# RZN2L register map
Vendor: Renesas Electronics Corporation; Series: RZN; File version: 1.30.01
CPU: other r0p0, little endian, MPU, no FPU, VTOR, 4 interrupt priority bits, 624 interrupts
Registers are 32-bit, read-write, reset 0x0 unless marked. A register's access mark holds for its fields unless they carry their own. Offsets are from the block's base; [hi:lo] are bit positions; {n}, {i} and the like mark numbered series; 'fields as' and 'values as' point back to an identical list.

## ETHSW (part 2 of 3) — Ethernet Switch
Base 0x80120000
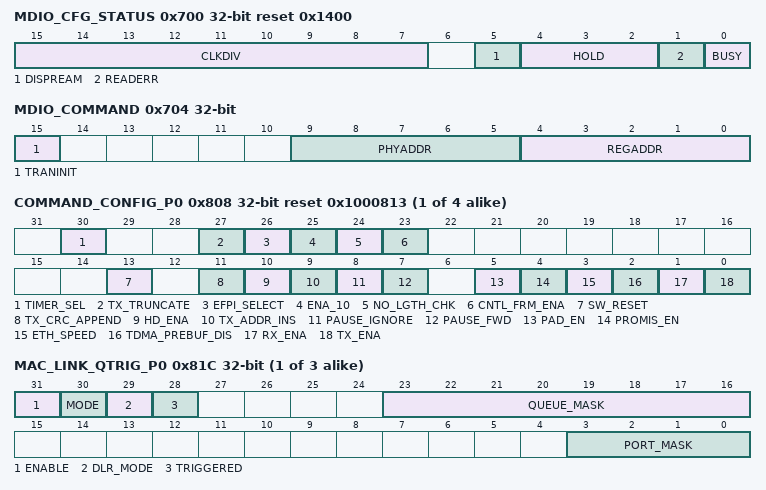
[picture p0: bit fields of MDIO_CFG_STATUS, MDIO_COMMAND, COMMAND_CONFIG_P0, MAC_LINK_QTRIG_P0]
0x700 MDIO_CFG_STATUS reset 0x1400 — MDIO Configuration and Status Register
  [15:7] CLKDIV — MDIO Clock Divisor
  [5] DISPREAM — Disable Preamble
    0=Enable Preamble; 1=Disable Preamble
  [4:2] HOLD — MDIO Hold Time Setting
    0=1 PCLKM clock cycle (default); 1=3 PCLKM clock cycles; 2=5 PCLKM clock cycles; 3=7 PCLKM clock cycles; 4=9 PCLKM clock cycles; 5=11 PCLKM clock cycles; 6=13 PCLKM clock cycles; 7=15 PCLKM clock cycles
  [1] READERR ro — MDIO Read Error
  [0] BUSY ro — MDIO Busy
0x704 MDIO_COMMAND — MDIO PHY Command Register
  [15] TRANINIT — If set to 1, a read transaction is initiated.
  [9:5] PHYADDR — PHY Address
  [4:0] REGADDR — Register Address
0x708 MDIO_DATA
  [15:0] MDIO_DATA
{0x800+0x400*i} REV_P{i} (i=0..3) ro reset 0x10002 (reset mask 0xFFFFFFFA) — Port {i} MAC Core Revision (n = 0 to 3)
  [31:0] REV — MAC Core Revision
{0x808+0x400*i} COMMAND_CONFIG_P{i} (i=0..3) reset 0x1000813 — Port {i} Command Configuration Register (n = 0 to 3)
  [30] TIMER_SEL — Selects the default timer to use for timestamping operations on transmit and on receive. The value is used when not overridden by the PTP auto-response function, pattern matchers or force forwarding information in a management tag.
    0=Use timer 0; 1=Use timer 1
  [27] TX_TRUNCATE
  [26] EFPI_SELECT
    0=EFP disable; 1=EFP enable
  [25] ENA_10 — This bit has no effect except PHYSPEED bit of STATUS_Pn register.
  [24] NO_LGTH_CHK — Payload Length Check Disable
  [23] CNTL_FRM_ENA — MAC Control Frame Enable
  [13] SW_RESET — Self Clearing Reset Command Bit
  [11] TX_CRC_APPEND — Enable CRC Append on Transmit
  [10] HD_ENA — Enable auto full/half-duplex operation (set to 1) or full-duplex only (set to 0).
  [9] TX_ADDR_INS ro — Non writable bit, fixed to 0 always.
  [8] PAUSE_IGNORE — Ignore Pause Frame Quanta
  [7] PAUSE_FWD ro — Terminate/Forward Pause Frames
  [5] PAD_EN ro — Enable/Disable Frame Padding Remove on Receive
  [4] PROMIS_EN ro — Enable/Disable MAC Promiscuous Operation
  [3] ETH_SPEED — Operation Mode Definition
    0=10/100 Megabit mode; 1=1 Gigabit mode
  [2] TDMA_PREBUF_DIS — When set to 1, the MAC does not request a new frame from the IMC until the current frame is completed. This can cause the IPG between frames to be more than the value in TX_IPG_LENGTH.
  [1] RX_ENA — Enable/Disable MAC Receive Path
  [0] TX_ENA — Enable/Disable MAC Transmit Path
{0x80C+0x400*i} MAC_ADDR_0_P{i} (i=0..2) — Port {i} MAC Address Register 0 (n = 0 to 2)
  [31:0] MAC_ADDR — The first 4 bytes of the MAC address of the port. First byte is bits [7:0]. The MAC address is used on locally generated frames such as pause frames, peer-delay response.
{0x810+0x400*i} MAC_ADDR_1_P{i} (i=0..2) — Port {i} MAC Address Register 1 (n = 0 to 2)
  [15:0] MAC_ADDR — The last 2 bytes of the MAC address of the port. Bits [7:0] is the 5th byte and bits [15:8] is the 6th byte.
{0x814+0x400*i} FRM_LENGTH_P{i} (i=0..3) reset 0x5FE — Port {i} Maximum Frame Length Register (n = 0 to 3)
  [13:0] FRM_LENGTH — Maximum Frame Length
{0x818+0x400*i} PAUSE_QUANT_P{i} (i=0..3) ro reset 0xFFFF — Port {i} MAC Pause Quanta (n = 0 to 3)
  [15:0] PAUSE_QUANT — Pause Quanta
{0x81C+0x400*i} MAC_LINK_QTRIG_P{i} (i=0..2) — Port {i} Trigger Event Configuration Register (n = 0 to 2)
  [31] ENABLE — Write to 1 to enable the Link Queue Trigger feature. When the link status (phy_link) transitions from 1 -> 0, a trigger event is generated to the memory controller for the ports and queues indicated in PORT_MASK and QUEUE_MASK.
  [30] MODE — When set to 0, only a single Link_Status frame is generated. This is to prevent sending multiple frames due to link flapping.
  [29] DLR_MODE — When set to 0, the DLR state machine is ignored. When set to 1, the Link Queue Trigger occurs only if the DLR state machine is in the NORMAL or FAULT state.
  [28] TRIGGERED — When MODE is set to 1, TRIGGERED indicates whether a frame was transmitted. When MODE is set to 0, TRIGGERED is always 0. This flag clears when the register is written.
  [23:16] QUEUE_MASK — 1-bit per queue indicating from which queues a frame is transmitted from the ports indicated by PORT_MASK. A single frame is transmitted per indicated port in PORT_MASK among the queues indicated by QUEUE_MASK.
  [3:0] PORT_MASK — Per-port Bit Mask
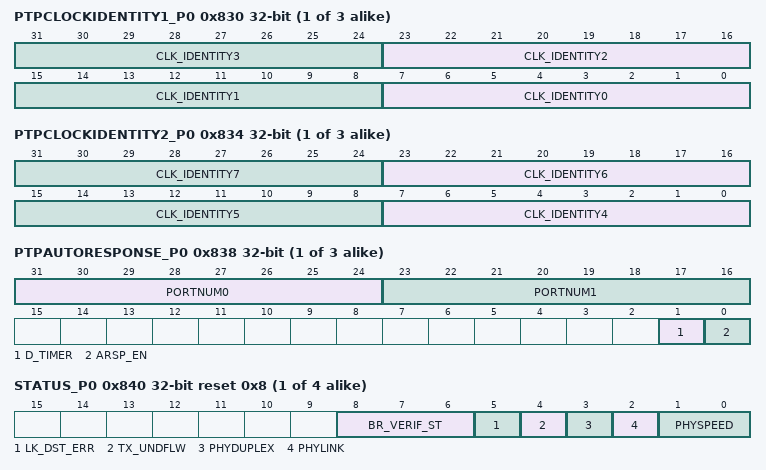
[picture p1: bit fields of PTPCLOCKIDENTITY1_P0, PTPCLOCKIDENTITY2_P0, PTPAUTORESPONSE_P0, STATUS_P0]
{0x830+0x400*i} PTPCLOCKIDENTITY1_P{i} (i=0..2) — Port {i} PTP Clock Identity 1 Register (n = 0 to 2)
  [8n+7:8n] CLK_IDENTITY{n} (n=0..3) — {n+20}, portIdentity.ClockIdentity[{n}]
{0x834+0x400*i} PTPCLOCKIDENTITY2_P{i} (i=0..2) — Port {i} PTP Clock Identity 2 Register (n = 0 to 2)
  [8n-25:8n-32] CLK_IDENTITY{n} (n=4..7) — {n+20}, portIdentity.ClockIdentity[{n}]
{0x838+0x400*i} PTPAUTORESPONSE_P{i} (i=0..2) — Port {i} PTP Auto Response Register (n = 0 to 2)
  [31:24] PORTNUM0 — 28, portIdentity.PortNumber[0] (msb)
  [23:16] PORTNUM1 — 29, portIdentity.PortNumber[1] (lsb)
  [1] D_TIMER — Default timer to use for auto-response generation
    0=Use timer 0; 1=Use timer 1
  [0] ARSP_EN — Auto Response Enable
{0x840+0x400*i} STATUS_P{i} (i=0..3) reset 0x8 (reset mask 0x1FC) — Port {i} Status Register
  [8:6] BR_VERIF_ST ro — Indicates the current status of the verification according to clause 30.14.1.2 of the 802.3br specification
    0=Unknown (during reset); 1=Initial (when preemption is disabled); 2=Verifying; 3=Succeeded; 4=Failed; 5=Disabled (if preempt verification is disabled)
  [5] LK_DST_ERR — Indicates that the L2 destination lookup process failed to complete in time before the next frame was received at the port. This should never occur under normal operation. The cause could be from IPG violations in the received frames.
  [4] TX_UNDFLW — Indicates that the transmit MAC underflow. This shall never occur during normal operation.
  [3] PHYDUPLEX ro — Duplex status from PHY interface
    0=half-duplex; 1=full-duplex
  [2] PHYLINK ro — Link status from PHY interface
    0=link down; 1=link up
  [1:0] PHYSPEED ro — Currently Active PHY Interface Speed
    0=10 Mbps; 1=100 Mbps; 2=1 Gbps
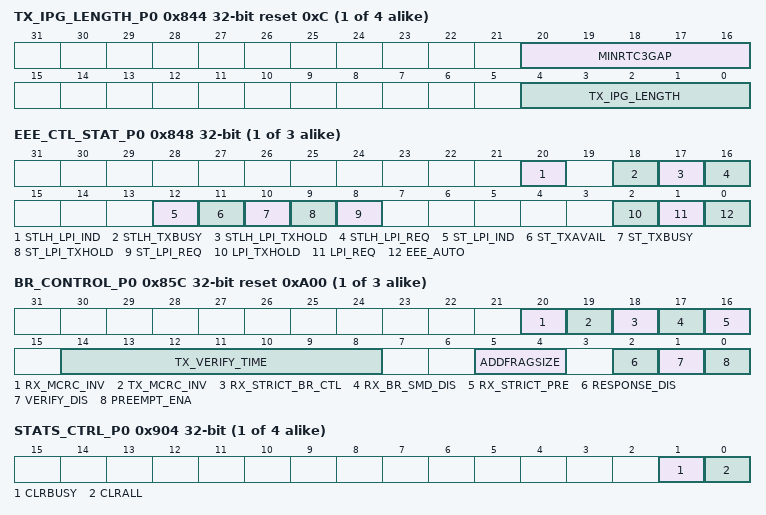
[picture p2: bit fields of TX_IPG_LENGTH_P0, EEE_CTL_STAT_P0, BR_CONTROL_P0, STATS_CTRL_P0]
{0x844+0x400*i} TX_IPG_LENGTH_P{i} (i=0..3) reset 0xC (reset mask 0x11001F) — Port {i} Transmit IPG Length Register (n = 0 to 3)
  [20:16] MINRTC3GAP
  [4:0] TX_IPG_LENGTH — Define transmit interpacket gap in octets. Allowed values are in the range of 8 to 31.
{0x848+0x400*i} EEE_CTL_STAT_P{i} (i=0..2) — Port {i} MAC EEE Functions Control and Status (n = 0 to 2)
  [20] STLH_LPI_IND ro — Status (latched high) of Received LPI (ST_LPI_IND)
  [18] STLH_TXBUSY ro — Status (latched high) if the MAC is/was Transmitting
  [17] STLH_LPI_TXHOLD ro — Status (latched high) of Internal LPI_TXHOLD to the MAC
  [16] STLH_LPI_REQ ro — Status (latched high) of Internal LPI_REQ to the MAC
  [12] ST_LPI_IND ro — Status (real time) of Received LPI
  [11] ST_TXAVAIL ro — Status (real time) if the MAC transmit FIFO has data available for transmission.
  [10] ST_TXBUSY ro — Status (real time) if the MAC is currently transmitting.
  [9] ST_LPI_TXHOLD ro — Status (real time) of Internal LPI_TXHOLD to the MAC
  [8] ST_LPI_REQ ro — Status (real time) of Internal LPI_REQ to the MAC
  [2] LPI_TXHOLD — MAC Transmission Hold
  [1] LPI_REQ — Request LPI Transmission when MAC Becomes Idle
  [0] EEE_AUTO — EEE Automatic Mode of Operation
{0x84C+0x400*i} EEE_IDLE_TIME_P{i} (i=0..2) — Port {i} EEE Idle Time Register (n = 0 to 2)
  [31:0] EEE_IDLE_TIME — Time (-1) the transmitter must be idle before transmission of LPI begins. A 32-bit value in steps of 32 switch operating clock cycles. A value of 0 disables the timer. The value must be set to 1 less count.
{0x850+0x400*i} EEE_TWSYS_TIME_P{i} (i=0..2) — Port {i} EEE Wake Up Time Register (n = 0 to 2)
  [31:0] EEE_WKUP_TIME — Time (-1) after PHY wakeup until the MAC is allowed to begin transmitting the first frame again. A 32-bit value in steps of switch operating clock cycles. A value of 0 disables the timer. The value must be set to 1 less count.
{0x854+0x400*i} IDLE_SLOPE_P{i} (i=0..3) — Port {i} MAC Traffic Shaper Bandwidth Control
  [10:0] IDLE_SLOPE — Traffic Shaper Bandwidth Control
{0x858+0x400*i} CT_DELAY_P{i} (i=0..2) — Port {i} Cut-Through Delay Indication Register
  [8:0] CT_DELAY — Delay Value in 400 ns / 40 ns / 8 ns increments (frequency of the MII PHY interface)
{0x85C+0x400*i} BR_CONTROL_P{i} (i=0..2) reset 0xA00 — Port {i} 802.3br Frame Configuration Register
  [20] RX_MCRC_INV — When set to 1, the 32-bit XOR mask used to calculate the mCRC for received frames is inverted. This bit must always be written to 0 and only used for debugging.
  [19] TX_MCRC_INV — When set to 1, the 32-bit XOR mask used to calculate the mCRC for transmitted frames is inverted. This bit must always be written to 0 and only used for debugging.
  [18] RX_STRICT_BR_CTL — When set to 1, strict checking of VERIFY and RESPONSE frames is enabled. When set to 1, the frame contents and frame length checks are also performed on these frames. The mCRC is always checked regardless of the value of this register. This bit must be set to 0 to be compliant with the functionality described in IEEE 802.3br.
  [17] RX_BR_SMD_DIS — When set to 1, the receiver does not decode the 802.3br SMDs and assumes all frames are express frames. This bit must be set to 0 for correct operation with 802.3br, and can be set to 1 when 802.3br is not enabled to avoid false detection of SMDs.
  [16] RX_STRICT_PRE — When set to 1, the preamble is checked so all bytes except the SFD are 0x55. When set to 0, only the last 2 bytes of the preamble are checked (SFD/SMD and FRAG_COUNT). It is recommended to set this bit to 1 to comply with the 802.3br specification. This bit must be set to 0 if only non-802.3br traffic is expected (for example, normal Ethernet traffic) and if custom preamble is used.
  [14:8] TX_VERIFY_TIME — Preemption verification timeout in milliseconds.
  [5:4] ADDFRAGSIZE — Minimum fragment size in increments of 64 bytes.
  [2] RESPONSE_DIS — When set to 1 prevents the MAC from responding to "verify" frames.
  [1] VERIFY_DIS — When set to 1, disables the verify process required for preemption operation.
  [0] PREEMPT_ENA — When set to 1, enables 802.3br Frame Preemption.
{0x868+0x400*i} AFRAMESTRANSMITTEDOK_P{i} (i=0..3) ro — Port {i} MAC Transmitted Valid Frame Count Register (n = 0 to 3)
  [31:0] TXVALIDCOUNT — PORT n, this field indicates the number of MAC Valid Transmitted, including pause.
{0x86C+0x400*i} AFRAMESRECEIVEDOK_P{i} (i=0..3) ro — Port {i} MAC Received Valid Frame Count Register (n = 0 to 3)
  [31:0] RXVALIDCOUNT — PORT n, this field indicates the number of MAC Valid Received, including pause.
{0x870+0x400*i} AFRAMECHECKSEQUENCEERRORS_P{i} (i=0..3) ro — Port {i} MAC FCS Error Frame Count Register (n = 0 to 3)
  [31:0] FCSERRCOUNT — PORT n, this field indicates the number of MAC Valid Length but CRC error.
{0x874+0x400*i} AALIGNMENTERRORS_P{i} (i=0..3) ro — Port {i} MAC Alignment Error Frame Count Register (n = 0 to 3)
  [31:0] ALGNERRCOUNT — PORT n, this field indicates the number of MAC Odd Number of Nibbles (MII) Received.
{0x878+0x400*i} AOCTETSTRANSMITTEDOK_P{i} (i=0..3) ro — Port {i} MAC Transmitted Valid Frame Octets Register (n = 0 to 3)
  [31:0] TXVALIDOCTETS — PORT n, this field indicates the octets (the payload only) of MAC Valid Transmitted.
{0x87C+0x400*i} AOCTETSRECEIVEDOK_P{i} (i=0..3) ro — Port {i} MAC Received Valid Frame Octets Register (n = 0 to 3)
  [31:0] RXVALIDOCTETS — PORT n, this field indicates the octets (the payload only) of MAC Valid Received.
{0x880+0x400*i} ATXPAUSEMACCTRLFRAMES_P{i} (i=0..3) ro — Port {i} MAC Transmitted Pause Frame Count Register (n = 0 to 3)
  [31:0] TXPAUSECOUNT — PORT n, this field indicates the number of MAC Valid Pause Transmitted.
{0x884+0x400*i} ARXPAUSEMACCTRLFRAMES_P{i} (i=0..3) ro — Port {i} MAC Received Pause Frame Count Register (n = 0 to 3)
  [31:0] RXPAUSECOUNT — PORT n, this field indicates the number of MAC Valid Pause Received.
{0x888+0x400*i} IFINERRORS_P{i} (i=0..3) ro — Port {i} MAC Input Error Count Register (n = 0 to 3)
  [31:0] INERRCOUNT — PORT n, this field indicates the number of MAC Any Error During Reception such as CRC, Length, PHY Error, RX FIFO Overflow.
{0x88C+0x400*i} IFOUTERRORS_P{i} (i=0..3) ro — Port {i} MAC Output Error Count Register (n = 0 to 3)
  [31:0] OUTERRCOUNT — PORT n, this field indicates the number of MAC Frame Transmitted with PHY error.
{0x890+0x400*i} IFINUCASTPKTS_P{i} (i=0..3) ro — Port {i} MAC Received Unicast Frame Count Register (n = 0 to 3)
  [31:0] RXUCASTCOUNT — PORT n, this field indicates the number of MAC Unicast Frame Valid Received.
{0x894+0x400*i} IFINMULTICASTPKTS_P{i} (i=0..3) ro — Port {i} MAC Received Multicast Frame Count Register (n = 0 to 3)
  [31:0] RXMCASTCOUNT — PORT n, this field indicates the number of MAC Multicast Frame Valid Received.
{0x898+0x400*i} IFINBROADCASTPKTS_P{i} (i=0..3) ro — Port {i} MAC Received Broadcast Frame Count Register (n = 0 to 3)
  [31:0] RXBCASTCOUNT — PORT n, this field indicates the number of MAC Broadcast Frame Valid Received.
{0x89C+0x400*i} IFOUTDISCARDS_P{i} (i=0..3) ro — Port {i} MAC Discarded Outbound Frame Count Register (n = 0 to 3)
  [31:0] DISCOBCOUNT — Not Applicable
{0x8A0+0x400*i} IFOUTUCASTPKTS_P{i} (i=0..3) ro — Port {i} MAC Transmitted Unicast Frame Count Register (n = 0 to 3)
  [31:0] TXUCASTCOUNT — PORT n, this field indicates the number of MAC Unicast Frame Valid Transmitted.
{0x8A4+0x400*i} IFOUTMULTICASTPKTS_P{i} (i=0..3) ro — Port {i} MAC Transmitted Multicast Frame Count Register (n = 0 to 3)
  [31:0] TXMCASTCOUNT — PORT n, this field indicates the number of MAC Multicast Frame Valid Transmitted.
{0x8A8+0x400*i} IFOUTBROADCASTPKTS_P{i} (i=0..3) ro — Port {i} MAC Transmitted Broadcast Frame Count Register (n = 0 to 3)
  [31:0] TXBCASTCOUNT — PORT n, this field indicates the number of MAC Broadcast Frame Valid Transmitted.
{0x8AC+0x400*i} ETHERSTATSDROPEVENTS_P{i} (i=0..3) ro — Port {i} MAC Dropped Frame Count Register (n = 0 to 3)
  [31:0] DROPCOUNT — PORT n, this field indicates the number of MAC RX FIFO Full at frame start.
{0x8B0+0x400*i} ETHERSTATSOCTETS_P{i} (i=0..3) ro — Port {i} MAC All Frame Octets Register (n = 0 to 3)
  [31:0] ALLOCTETS
{0x8B4+0x400*i} ETHERSTATSPKTS_P{i} (i=0..3) ro — Port {i} MAC All Frame Count Register (n = 0 to 3)
  [31:0] ALLCOUNT
{0x8B8+0x400*i} ETHERSTATSUNDERSIZEPKTS_P{i} (i=0..3) ro — Port {i} MAC Too Short Frame Count Register (n = 0 to 3)
  [31:0] TOOSHRTCOUNT — PORT n, this field indicates the number of MAC too Short, Good CRC.
{0x8BC+0x400*i} ETHERSTATSOVERSIZEPKTS_P{i} (i=0..3) ro — Port {i} MAC Too Long Frame Count Register (n = 0 to 3)
  [31:0] TOOLONGCOUNT — PORT n, this field indicates the number of MAC too Long, Good CRC.
{0x8C0+0x400*i} ETHERSTATSPKTS64OCTETS_P{i} (i=0..3) ro — Port {i} MAC 64 Octets Frame Count Register (n = 0 to 3)
  [31:0] OCTCNT64 — PORT n, this field indicates the number of MAC All Frames, Good and Bad (Packet Size: 64 bytes).
{0x8C4+0x400*i} ETHERSTATSPKTS65TO127OCTETS_P{i} (i=0..3) ro — Port {i} MAC 65 to 127 Octets Frame Count Register (n = 0 to 3)
  [31:0] OCTCNT65T127 — PORT n, this field indicates the number of MAC All Frames, Good and Bad (Packet Size: 65 to 127 bytes).
{0x8C8+0x400*i} ETHERSTATSPKTS128TO255OCTETS_P{i} (i=0..3) ro — Port {i} MAC 128 to 255 Octets Frame Count Register (n = 0 to 3)
  [31:0] OCTCNT128T255 — PORT n, this field indicates the number of MAC All Frames, Good and Bad (Packet Size: 128 to 255 bytes).
{0x8CC+0x400*i} ETHERSTATSPKTS256TO511OCTETS_P{i} (i=0..3) ro — Port {i} MAC 256 to 511 Octets Frame Count Register (n = 0 to 3)
  [31:0] OCTCNT256T511 — PORT n, this field indicates the number of MAC All Frames, Good and Bad (Packet Size: 256 to 511 bytes).
{0x8D0+0x400*i} ETHERSTATSPKTS512TO1023OCTETS_P{i} (i=0..3) ro — Port {i} MAC 512 to 1023 Octets Frame Count Register (n = 0 to 3)
  [31:0] OCTCNT512T1023 — PORT n, this field indicates the number of MAC All Frames, Good and Bad (Packet Size: 512 to 1023 bytes).
{0x8D4+0x400*i} ETHERSTATSPKTS1024TO1518OCTETS_P{i} (i=0..3) ro — Port {i} MAC 1024 to 1518 Octets Frame Count Register (n = 0 to 3)
  [31:0] OCTCNT1024T1518 — PORT n, this field indicates the number of MAC All Frames, Good and Bad (Packet Size: 1024 to 1518 bytes).
{0x8D8+0x400*i} ETHERSTATSPKTS1519TOXOCTETS_P{i} (i=0..3) ro — Port {i} MAC Over 1519 Octets Frame Count Register (n = 0 to 3)
  [31:0] OCTCNT1519TX — PORT n, this field indicates the number of MAC all Frames, Good and Bad (Packet Size: over 1519 bytes).
{0x8DC+0x400*i} ETHERSTATSJABBERS_P{i} (i=0..3) ro — Port {i} MAC Jabbers Frame Count Register (n = 0 to 3)
  [31:0] JABBERCOUNT — PORT n, this field indicates the number of MAC too Long, Bad CRC.
{0x8E0+0x400*i} ETHERSTATSFRAGMENTS_P{i} (i=0..3) ro — Port {i} MAC Fragment Frame Count Register (n = 0 to 3)
  [31:0] FRAGCOUNT — PORT n, this field indicates the number of MAC too Short, Bad CRC.
{0x8E8+0x400*i} VLANRECEIVEDOK_P{i} (i=0..3) ro — Port {i} MAC Received VLAN Tagged Frame Count Register (n = 0 to 3)
  [31:0] RXVLANTAGCNT — PORT n, this field indicates the number of Good Frames with VLAN Tag Received.
{0x8F4+0x400*i} VLANTRANSMITTEDOK_P{i} (i=0..3) ro — Port {i} MAC Transmitted VLAN Tagged Frame Count Register (n = 0 to 3)
  [31:0] TXVLANTAGCNT — PORT n, this field indicates the number of Good Frames with VLAN Tag Transmitted.
{0x8F8+0x400*i} FRAMESRETRANSMITTED_P{i} (i=0..3) ro — Port {i} MAC Retransmitted Frame Count Register (n = 0 to 3)
  [31:0] RETXCOUNT — PORT n, this field indicates the number of Transmitted Frames that experienced a collision and were retransmitted.
{0x900+0x400*i} STATS_HIWORD_P{i} (i=0..3) ro — Port {i} MAC Statistics Counter High Word Register (n = 0 to 3)
  [31:0] STATS_HIWORD — The latched upper 32-bit of the 64 bits MAC Statistics Counter Last Read
{0x904+0x400*i} STATS_CTRL_P{i} (i=0..3) — Port {i} MAC Statistics Control Register (n = 0 to 3)
  [1] CLRBUSY ro — Clear in Progress Indication
  [0] CLRALL — Self Clearing Counter Initialize Command
{0x908+0x400*i} STATS_CLEAR_VALUELO_P{i} (i=0..3) — Port {i} MAC Statistics Clear Value Lower Register (n = 0 to 3)
  [31:0] STATS_CLEAR_VALUELO — PORT n, lower 32-bit of 64 bits value loaded into all counters when clearing all counters with STATS_CTRL_Pn.CLRALL command for test purposes. These bits should be set to 0 normally.
{0x90C+0x400*i} STATS_CLEAR_VALUEHI_P{i} (i=0..3) — Port {i} MAC Statistics Clear Value Higher Register (n = 0 to 3)
  [31:0] STATS_CLEAR_VALUEHI — PORT n, upper 32-bit of 64 bits value loaded into all counters when clearing all counters with STATS_CTRL_Pn.CLRALL command for test purposes. These bits should be set to 0 normally.
{0x910+0x400*i} ADEFERRED_P{i} (i=0..3) ro — Port {i} MAC Deferred Count Register (n = 0 to 3)
  [31:0] DEFERCOUNT — PORT n, this field indicates the number of Frame Transmitted without collision but was deferred at begin.
{0x914+0x400*i} AMULTIPLECOLLISIONS_P{i} (i=0..3) ro — Port {i} MAC Multiple Collision Count Register (n = 0 to 3)
  [31:0] COUNTAFTMLTCOLL — PORT n, this field indicates the number of Good Frame Transmit after multiple collisions.
{0x918+0x400*i} ASINGLECOLLISIONS_P{i} (i=0..3) ro — Port {i} MAC Single Collision Count Register (n = 0 to 3)
  [31:0] COUNTAFTSNGLCOLL — PORT n, this field indicates the number of Good Frame Transmit after single collision.
{0x91C+0x400*i} ALATECOLLISIONS_P{i} (i=0..3) ro — Port {i} MAC Late Collision Count Register (n = 0 to 3)
  [31:0] LATECOLLCOUNT — PORT n, this field indicates the number of too Late Collision. Frame was aborted and not retransmitted.
{0x920+0x400*i} AEXCESSIVECOLLISIONS_P{i} (i=0..3) ro — Port {i} MAC Excessive Collision Count Register (n = 0 to 3)
  [31:0] EXCCOLLCOUNT — PORT n, this field indicates the number of Frames Discarded due to 16 consecutive collisions.
{0x924+0x400*i} ACARRIERSENSEERRORS_P{i} (i=0..3) ro — Port {i} MAC Carrier Sense Error Count Register (n = 0 to 3)
  [31:0] CSERRCOUNT — PORT n, increments during Transmission without Collisions the PHY Carrier Sense Signal (RX_CRS) dropped or never asserted.
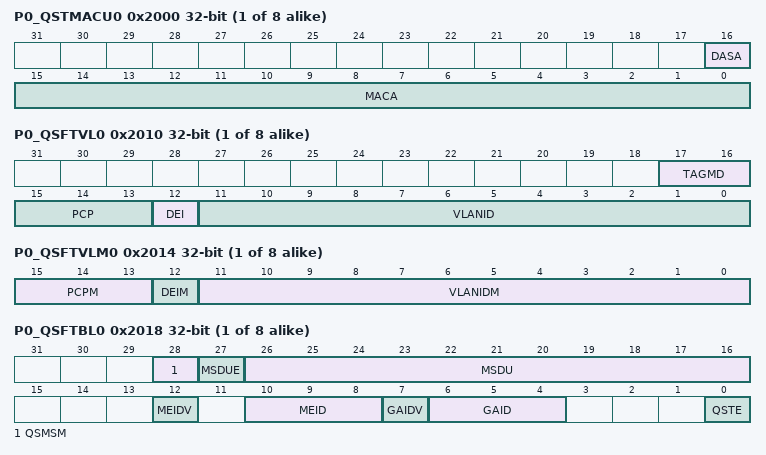
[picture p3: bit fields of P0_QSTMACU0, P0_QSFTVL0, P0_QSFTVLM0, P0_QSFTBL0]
{0x2000+0x28*i} P0_QSTMACU{i} (i=0..7) — Qci Stream Filter Table MAC Address Upper Part
  [16] DASA — MAC address (MACA) select
    0=MACA is a source address; 1=MACA is a destination address
  [15:0] MACA — Qci stream filter table MAC address[47:32]
{0x2004+0x28*i} P0_QSTMACD{i} (i=0..7) — Qci Stream Filter Table MAC Address Downer Part
  [31:0] MACA — Qci stream filter table MAC address[31:0]
{0x2008+0x28*i} P0_QSTMAMU{i} (i=0..7) — Qci Stream Filter Table MAC Address Mask Upper Part
  [15:0] MACAM — Qci stream filter table MAC address bit mask[47:32]
{0x200C+0x28*i} P0_QSTMAMD{i} (i=0..7) — Qci Stream Filter Table MAC Address Mask Downer Part
  [31:0] MACAM — Qci stream filter table MAC address bit mask[31:0]
{0x2010+0x28*i} P0_QSFTVL{i} (i=0..7) — Qci Stream Filter Table VLAN
  [17:16] TAGMD
    0=Un Tagged (the frame must be untagged to match to this filter); 1=C-Tagged (the frame must be C-Tagged to match to this filter); 3=Do not check VLAN Tag (VLAN Tag check is skipped. All frames either untagged or tagged with any VLAN/PCP/DEI may match this filter.)
  [15:13] PCP
  [12] DEI
  [11:0] VLANID
{0x2014+0x28*i} P0_QSFTVLM{i} (i=0..7) — Qci Stream Filter Table VLAN Mask
  [15:13] PCPM — Qci stream filter table VLAN PCP[2:0] bit mask
  [12] DEIM
    0=No bit mask; 1=Bit mask (the bit value of the DEI is ignored, any value matches)
  [11:0] VLANIDM — Qci stream filter table VLAN ID[11:0] bit mask
{0x2018+0x28*i} P0_QSFTBL{i} (i=0..7) — Qci Stream Filter Table SDU/Gate/Meter ID
  [28] QSMSM — Qci stream MSDU mode
    0=No effect; 1=When a frame is discard by MSDU over, all frames are dropped until software clears Pn_QSEIS.QSMOIS[s]
  [27] MSDUE
    0=Check disable; 1=Check enable
  [26:16] MSDU — Qci stream filter table max SDU size
  [12] MEIDV
    0=Meter Check disable; 1=Meter Check enable
  [10:8] MEID
  [7] GAIDV
    0=Gating Check disable; 1=Gating Check enable
  [6:4] GAID
  [0] QSTE
    0=Stream filter Table disable (All frame unmatch); 1=Stream filter Table enable
{0x201C+0x28*i} P0_QSMFC{i} (i=0..7) ro — Qci Stream Match Packet Count
  [15:0] QSMFC — Qci stream match packet count
{0x2020+0x28*i} P0_QMSPPC{i} (i=0..7) ro — Qci MSDU Passed Packet Count
  [15:0] QMSPPC — Qci msdu passed packet count
{0x2024+0x28*i} P0_QMSRPC{i} (i=0..7) ro — Qci MSDU Reject Packet Count
  [15:0] QMSRPC — Qci MSDU rejected packet count
{0x21E8+0x400*i} P{i}_QSEIS (i=0..2) — Qci Stream Filter Error Interrupt Status (SDU Oversize)
  [7:0] QSMOIS — MSDU oversize frames Interrupt status[s]
{0x21EC+0x400*i} P{i}_QSEIE (i=0..2) — Qci Stream Filter Error Interrupt Enable
  [7:0] QSMOIE — MSDU oversize frames Interrupt Enable[s]
{0x21F0+0x400*i} P{i}_QSEID (i=0..2) wo — Qci Stream Filter Error Interrupt Disable
  [7:0] QSMOID — MSDU oversize frames Interrupt Disable[s]
{0x2200+0x400*i} P{i}_QGMOD (i=0..2) — Qci Gate Mode Register
  [7:0] QGMOD — Flow gate mode[g]
{0x2204+0x400*i} P{i}_QGPPC (i=0..2) ro — Qci Gate (All) Passed Packet Count Port {i}
  [15:0] QGPPC — Qci gate passed packet count
{0x2208+8i} P0_QGDPC{i} (i=0..7) ro — Qci Gate {i} Dropped Packet Count Port n
  [15:0] QGDPC — Qci gate dropped packet count
{0x2244+0x400*i} P{i}_QGEIS (i=0..2) — Qci Gate Error Interrupt Status
  [7:0] QGMOIS — Gating error Interrupt status[g]
{0x2248+0x400*i} P{i}_QGEIE (i=0..2) — Qci Gate Error Interrupt Enable
  [7:0] QGMOIE — Gating error Interrupt Enable[g]
{0x224C+0x400*i} P{i}_QGEID (i=0..2) wo — Qci Gate Error Interrupt Disable
  [7:0] QGMOID — Gating error Interrupt Disable[g]
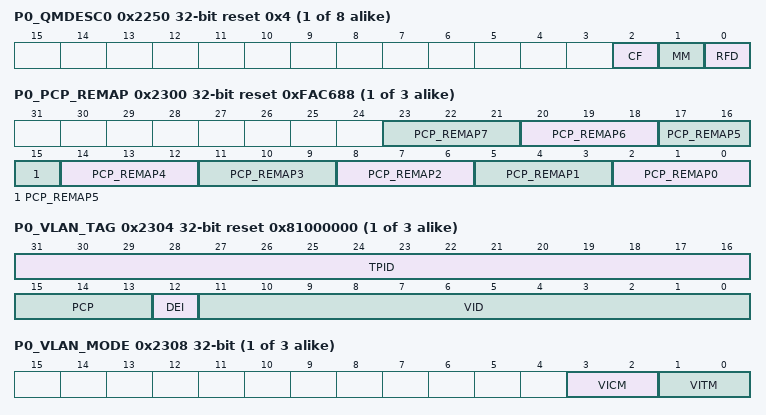
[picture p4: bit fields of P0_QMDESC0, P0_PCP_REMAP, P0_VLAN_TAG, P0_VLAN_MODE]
{0x2250+0x14*i} P0_QMDESC{i} (i=0..7) reset 0x4 — Qci Port n Flow Meter {i} Descriptor Register
  [2] CF — Coupling flag
  [1] MM — Flow meter mode
    0=No effect; 1=When discard frame by Flow Meter, all frames are dropped until software clears Pn_QMEIS.QRFIS[m]
  [0] RFD — Red frame drop
    0=A red frame is not dropped; 1=A red frame is dropped
{0x2254+0x14*i} P0_QMCBSC{i} (i=0..7) — Qci Meter CBS Configuration Port n, Meter {i}
  [17:0] CBS — CBS (Committed Burst Size)
{0x2258+0x14*i} P0_QMCIRC{i} (i=0..7) — Qci Meter CIR Configuration n {i}
  [16:0] CIR — CIR (Committed Information Rate)
{0x225C+0x14*i} P0_QMGPC{i} (i=0..7) ro — Qci Meter Green Packet Count
  [15:0] QMGPC — Qci meter green packet count
{0x2260+0x14*i} P0_QMRPC{i} (i=0..7) ro — Qci Meter Red Packet Count
  [15:0] QMRPC — Qci meter red packet count
{0x22F0+0x400*i} P{i}_QMEC (i=0..2) — Qci Meter Enable Configuration
  [7:0] ME — Enable meter[m]
{0x22F4+0x400*i} P{i}_QMEIS (i=0..2) — Qci Meter Error Interrupt Status
  [7:0] QRFIS — Red frames Interrupt status[m]
{0x22F8+0x400*i} P{i}_QMEIE (i=0..2) — Qci Meter Error Interrupt Enable
  [7:0] QRFIE — Red frames Interrupt Enable[m]
{0x22FC+0x400*i} P{i}_QMEID (i=0..2) wo — Qci Meter Error Interrupt Disable
  [7:0] QRFID — Red frames Interrupt Disable[m]
{0x2300+0x400*i} P{i}_PCP_REMAP (i=0..2) reset 0xFAC688 — Port {i} VLAN Priority Code Point (PCP) Remap
  [3n+2:3n] PCP_REMAP{n} (n=0..7)
{0x2304+0x400*i} P{i}_VLAN_TAG (i=0..2) reset 0x81000000 — Port {i} VLAN TAG Information for Priority Regeneration
  [31:16] TPID, [15:13] PCP, [12] DEI, [11:0] VID
{0x2308+0x400*i} P{i}_VLAN_MODE (i=0..2) — Port {i} VLAN Mode
  [3:2] VICM — VLAN input verification mode
    {v}=Mode {v} (v=0..3)
  [1:0] VITM — VLAN input tagging mode
    0=Disabled, VLAN tag is neither added nor overwritten; 1=Single Tagging with Passthrough/ VLAN ID (VID) Overwrite; 2=Single Tagging with Replace; 3=Tag always
{0x230C+0x400*i} P{i}_VIC_DROP_CNT (i=0..2) ro — Port {i} VLAN Ingress Check Drop Frame Counter
  [15:0] VIC_DROP_CNT — Port n VLAN ingress check drop frame count
{0x2328+0x400*i} P{i}_LOOKUP_HIT_CNT (i=0..2) ro — Port {i} DST Address Lookup Hit Counter
  [23:0] LOOKUP_HIT_CNT — Port n Lookup hit count
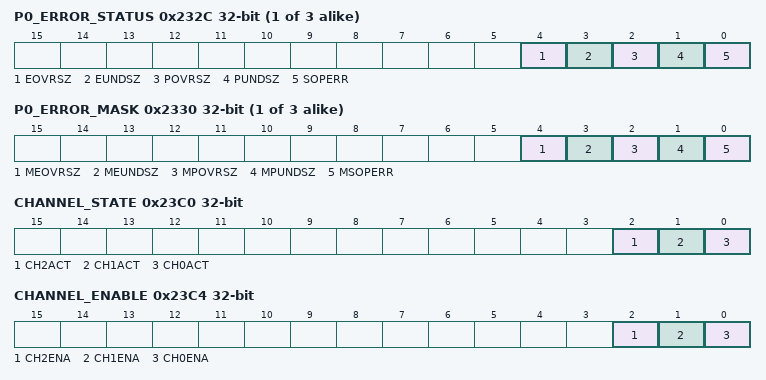
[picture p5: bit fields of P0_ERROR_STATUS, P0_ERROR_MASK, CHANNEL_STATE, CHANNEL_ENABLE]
{0x232C+0x400*i} P{i}_ERROR_STATUS (i=0..2) — Port {i} Frame Parser Runtime Error Status
  [4] EOVRSZ — Express frame over size error detected in frame parser
  [3] EUNDSZ — Express frame under size error detected in frame parser
  [2] POVRSZ — Preemptable frame over size error detected in frame parser
  [1] PUNDSZ — Preemptable frame under size error detected in frame parser
  [0] SOPERR — SOP error detected in frame parser
{0x2330+0x400*i} P{i}_ERROR_MASK (i=0..2) — Port {i} Frame Parser Runtime Error Mask
  [4] MEOVRSZ — Error mask of EOVRSZ (Express frame over size error)
  [3] MEUNDSZ — Error mask of EUNDSZ (Express frame under size error)
  [2] MPOVRSZ — Error mask of POVRSZ (Preemptable frame over size error)
  [1] MPUNDSZ — Error mask of PUNDSZ (Preemptable frame under size error)
  [0] MSOPERR — Error mask of SOPERR (SOP error)
0x23C0 CHANNEL_STATE ro — Enable/Disable State of Ingress Channels
  [2] CH2ACT
    0=Channel port 2 is in reset. No frames are forwarded.; 1=Channel port 2 is enabled. Frames are forwarded and manipulated as configured.
  [1] CH1ACT
    0=Channel port 1 is in reset. No frames are forwarded.; 1=Channel port 1 is enabled. Frames are forwarded and manipulated as configured.
  [0] CH0ACT
    0=Channel port 0 is in reset. No frames are forwarded.; 1=Channel port 0 is enabled. Frames are forwarded and manipulated as configured.
0x23C4 CHANNEL_ENABLE wo reset not defined — Enable Operation of Channel
  [2] CH2ENA
    0=Ignored; 1=Enable Channel port 2
  [1] CH1ENA
    0=Ignored; 1=Enable Channel port 1
  [0] CH0ENA
    0=Ignored; 1=Enable Channel port 0
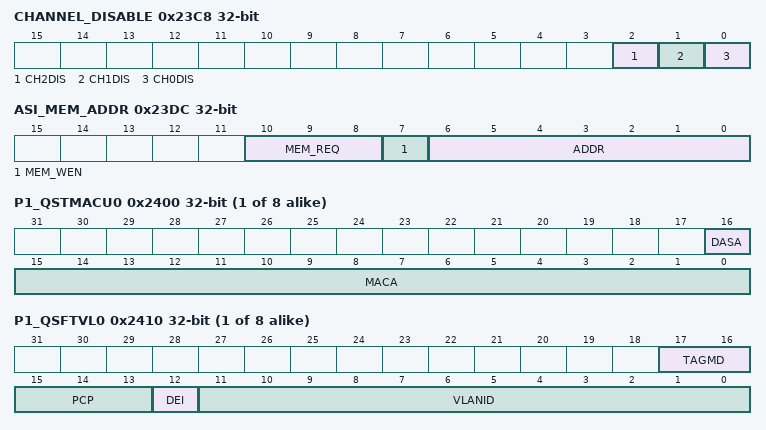
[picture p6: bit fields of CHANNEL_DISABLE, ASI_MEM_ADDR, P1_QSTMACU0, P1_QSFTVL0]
0x23C8 CHANNEL_DISABLE wo reset not defined — Disable and Reset Operation of Channel
  [2] CH2DIS
    0=Ignored; 1=Disable and reset Channel port 2
  [1] CH1DIS
    0=Ignored; 1=Disable and reset Channel port 1
  [0] CH0DIS
    0=Ignored; 1=Disable and reset Channel port 0
{0x23CC+4i} ASI_MEM_WDATA{i} (i=0..3) — Memory Write Data Word {i}
  [31:0] WDATA — Destination MAC address regeneration write data
0x23DC ASI_MEM_ADDR — Memory Address and R/W Control
  [10:8] MEM_REQ — Memory access request
  [7] MEM_WEN
    0=Read; 1=Write
  [6:0] ADDR — Memory access address
{0x23E0+4i} ASI_MEM_RDATA{i} (i=0..3) ro — Memory Read Data Word {i}
  [31:0] RDATA — Destination MAC address regeneration read data
{0x2400+0x28*i} P1_QSTMACU{i} (i=0..7) — Qci Stream Filter Table MAC Address Upper Part
  fields as P0_QSTMACU0
{0x2404+0x28*i} P1_QSTMACD{i} (i=0..7) — Qci Stream Filter Table MAC Address Downer Part
  [31:0] MACA — Qci stream filter table MAC address[31:0]
{0x2408+0x28*i} P1_QSTMAMU{i} (i=0..7) — Qci Stream Filter Table MAC Address Mask Upper Part
  [15:0] MACAM — Qci stream filter table MAC address bit mask[47:32]
{0x240C+0x28*i} P1_QSTMAMD{i} (i=0..7) — Qci Stream Filter Table MAC Address Mask Downer Part
  [31:0] MACAM — Qci stream filter table MAC address bit mask[31:0]
{0x2410+0x28*i} P1_QSFTVL{i} (i=0..7) — Qci Stream Filter Table VLAN
  fields as P0_QSFTVL0
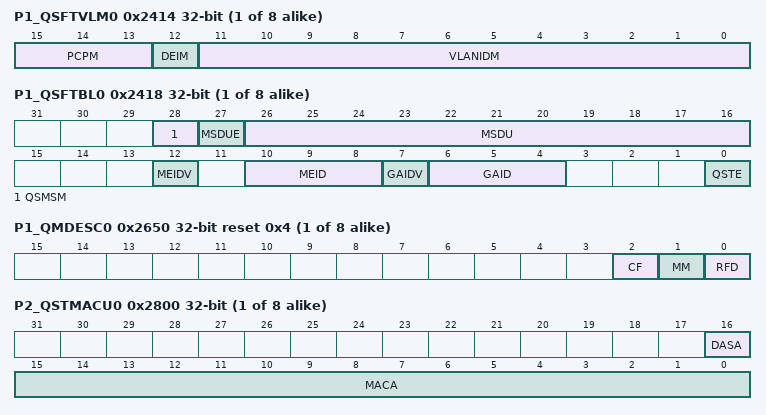
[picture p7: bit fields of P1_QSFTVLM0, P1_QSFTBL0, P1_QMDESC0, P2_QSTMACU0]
{0x2414+0x28*i} P1_QSFTVLM{i} (i=0..7) — Qci Stream Filter Table VLAN Mask
  fields as P0_QSFTVLM0
{0x2418+0x28*i} P1_QSFTBL{i} (i=0..7) — Qci Stream Filter Table SDU/Gate/Meter ID
  fields as P0_QSFTBL0
{0x241C+0x28*i} P1_QSMFC{i} (i=0..7) ro — Qci Stream Match Packet Count
  [15:0] QSMFC — Qci stream match packet count
{0x2420+0x28*i} P1_QMSPPC{i} (i=0..7) ro — Qci MSDU Passed Packet Count
  [15:0] QMSPPC — Qci msdu passed packet count
{0x2424+0x28*i} P1_QMSRPC{i} (i=0..7) ro — Qci MSDU Reject Packet Count
  [15:0] QMSRPC — Qci MSDU rejected packet count
{0x2608+8i} P1_QGDPC{i} (i=0..7) ro — Qci Gate {i} Dropped Packet Count Port n
  [15:0] QGDPC — Qci gate dropped packet count
{0x2650+0x14*i} P1_QMDESC{i} (i=0..7) reset 0x4 — Qci Port n Flow Meter {i} Descriptor Register
  fields as P0_QMDESC0
{0x2654+0x14*i} P1_QMCBSC{i} (i=0..7) — Qci Meter CBS Configuration Port n, Meter {i}
  [17:0] CBS — CBS (Committed Burst Size)
{0x2658+0x14*i} P1_QMCIRC{i} (i=0..7) — Qci Meter CIR Configuration n {i}
  [16:0] CIR — CIR (Committed Information Rate)
{0x265C+0x14*i} P1_QMGPC{i} (i=0..7) ro — Qci Meter Green Packet Count
  [15:0] QMGPC — Qci meter green packet count
{0x2660+0x14*i} P1_QMRPC{i} (i=0..7) ro — Qci Meter Red Packet Count
  [15:0] QMRPC — Qci meter red packet count
{0x2800+0x28*i} P2_QSTMACU{i} (i=0..7) — Qci Stream Filter Table MAC Address Upper Part
  fields as P0_QSTMACU0
{0x2804+0x28*i} P2_QSTMACD{i} (i=0..7) — Qci Stream Filter Table MAC Address Downer Part
  [31:0] MACA — Qci stream filter table MAC address[31:0]
{0x2808+0x28*i} P2_QSTMAMU{i} (i=0..7) — Qci Stream Filter Table MAC Address Mask Upper Part
  [15:0] MACAM — Qci stream filter table MAC address bit mask[47:32]
{0x280C+0x28*i} P2_QSTMAMD{i} (i=0..7) — Qci Stream Filter Table MAC Address Mask Downer Part
  [31:0] MACAM — Qci stream filter table MAC address bit mask[31:0]
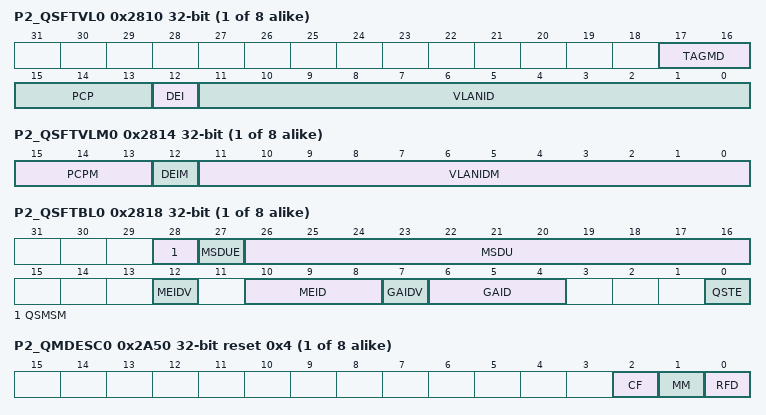
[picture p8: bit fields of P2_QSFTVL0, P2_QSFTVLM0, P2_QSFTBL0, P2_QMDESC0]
{0x2810+0x28*i} P2_QSFTVL{i} (i=0..7) — Qci Stream Filter Table VLAN
  fields as P0_QSFTVL0
{0x2814+0x28*i} P2_QSFTVLM{i} (i=0..7) — Qci Stream Filter Table VLAN Mask
  fields as P0_QSFTVLM0
{0x2818+0x28*i} P2_QSFTBL{i} (i=0..7) — Qci Stream Filter Table SDU/Gate/Meter ID
  fields as P0_QSFTBL0
{0x281C+0x28*i} P2_QSMFC{i} (i=0..7) ro — Qci Stream Match Packet Count
  [15:0] QSMFC — Qci stream match packet count
{0x2820+0x28*i} P2_QMSPPC{i} (i=0..7) ro — Qci MSDU Passed Packet Count
  [15:0] QMSPPC — Qci msdu passed packet count
{0x2824+0x28*i} P2_QMSRPC{i} (i=0..7) ro — Qci MSDU Reject Packet Count
  [15:0] QMSRPC — Qci MSDU rejected packet count
{0x2A08+8i} P2_QGDPC{i} (i=0..7) ro — Qci Gate {i} Dropped Packet Count Port n
  [15:0] QGDPC — Qci gate dropped packet count
{0x2A50+0x14*i} P2_QMDESC{i} (i=0..7) reset 0x4 — Qci Port n Flow Meter {i} Descriptor Register
  fields as P0_QMDESC0
{0x2A54+0x14*i} P2_QMCBSC{i} (i=0..7) — Qci Meter CBS Configuration Port n, Meter {i}
  [17:0] CBS — CBS (Committed Burst Size)
{0x2A58+0x14*i} P2_QMCIRC{i} (i=0..7) — Qci Meter CIR Configuration n {i}
  [16:0] CIR — CIR (Committed Information Rate)
{0x2A5C+0x14*i} P2_QMGPC{i} (i=0..7) ro — Qci Meter Green Packet Count
  [15:0] QMGPC — Qci meter green packet count
{0x2A60+0x14*i} P2_QMRPC{i} (i=0..7) ro — Qci Meter Red Packet Count
  [15:0] QMRPC — Qci meter red packet count
0x3404 STATN_STATUS ro — Statistics Status Register
  [0] BUSY — Statistics module is busy
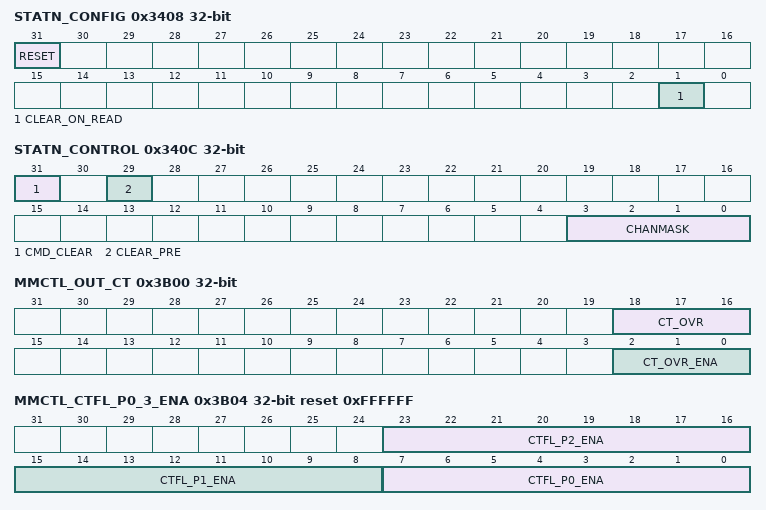
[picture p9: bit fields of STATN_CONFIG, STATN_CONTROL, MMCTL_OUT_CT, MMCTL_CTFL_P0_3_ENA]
0x3408 STATN_CONFIG — Statistics Configure Register
  [31] RESET — When set to 1, all internal functions are aborted and return to a stable state (flushes prescalers). It also triggers a clear of all counter memory (all ports are cleared) by setting STATN_CONTROL.CMD_CLEAR with all mask bits. Capture memory is not reset.
  [1] CLEAR_ON_READ — When set to 1, a read to a counter resets it to 0. When set to 0 (default), counters are not affected by read.
0x340C STATN_CONTROL — Statistics Control Register
  [31] CMD_CLEAR — Clear Channel Counters Command
  [29] CLEAR_PRE — Clear the internal pre-scaler counters of ports when a clear occurs. This bit can be used together with the CMD_CLEAR command to clear the internal pre-scaler counters of the ports.
  [3:0] CHANMASK — One bit per port. Bit 0 = port 0, bit 1 = port 1, and so on.
0x3410 STATN_CLEARVALUE_LO — Statistics Clear Value Lower Register
  [31:0] STATN_CLEARVALUE_LO — 32-bit value written into statistics memory when a clear command (STATN_CONTROL.CMD_CLEAR) is triggered (see ), or when a clear-after-read is used.
{0x3468+0x48*i} ODISC{i} (i=0..3) ro — Port {i} Discarded Outgoing Frame Count Register
  [31:0] ODISC — Port n outgoing frames discarded due to output queue congestion.
{0x346C+0x48*i} IDISC_VLAN{i} (i=0..3) ro — Port {i} Discarded Incoming VLAN Tagged Frame Count Register
  [31:0] IDISC_VLAN — Port n incoming frames discarded due to mismatching or missing VLAN ID while VLAN verification was enabled.
{0x3470+0x48*i} IDISC_UNTAGGED{i} (i=0..3) ro — Port {i} Discarded Incoming VLAN Untagged Frame Count Register
  [31:0] IDISC_UNTAGGED — Port n incoming frames discarded due to missing VLAN tag.
{0x3474+0x48*i} IDISC_BLOCKED{i} (i=0..3) ro — Port {i} Discarded Incoming Blocked Frame Count Register
  [31:0] IDISC_BLOCKED — Port n incoming frames discarded (after learning) as the port is configured in blocking mode.
{0x3478+0x48*i} IDISC_ANY{i} (i=0..3) ro — Port {i} Discarded Any Frame Count Register (n = 0 to 3)
  [31:0] IDISC_ANY — Port n total incoming frames discarded. This includes IDISC_VLAN, IDSIC_UNTAGGED, IDISC_SRCFLT, and IDISC_BLOCKED.
{0x347C+0x48*i} IDISC_SRCFLT{i} (i=0..2) ro — Port {i} Discarded Address Source Count Register
  [31:0] IDISC_SRCFLT — Port n counts the number of incoming frames discarded due to the MAC address source filter.
{0x3480+0x48*i} TX_HOLD_REQ_CNT{i} (i=0..2) ro — Port {i} TX Hold Request Count Register
  [31:0] TX_HOLD_REQ_CNT
{0x3484+0x48*i} TX_FRAG_CNT{i} (i=0..2) ro — Port {i} TX for Preemption Count Register
  [31:0] TX_FRAG_CNT — Port n increments when an additional mPacket is transmitted due to preemption.
{0x3488+0x48*i} RX_FRAG_CNT{i} (i=0..2) ro — Port {i} RX Continuation Count Register
  [31:0] RX_FRAG_CNT — Port n increments for every continuation mPacket received.
{0x348C+0x48*i} RX_ASSY_OK_CNT{i} (i=0..2) ro — Port {i} RX Preempted Frame Success Count Register
  [31:0] RX_ASSY_OK_CNT — Port n increments when a preempted frame is successfully assembled.
{0x3490+0x48*i} RX_ASSY_ERR_CNT{i} (i=0..2) ro — Port {i} RX Preempted Frame Incorrect Count Register
  [15:0] RX_ASSY_ERR_CNT — Port n increments when a preempted frame is incorrectly assembled.
{0x3494+0x48*i} RX_SMD_ERR_CNT{i} (i=0..2) ro — Port {i} RX SMD Frame Count Register
  [15:0] RX_SMD_ERR_CNT — Port n increments when a frame with an SMD-Cx is received and no assembly is in progress.
{0x3498+0x48*i} TX_VERIFY_OK_CNT{i} (i=0..2) ro — Port {i} TX VERIFY Frame Count Register
  [7:0] TX_VERIFY_OK_CNT — Port n increments for every VERIFY frame transmitted.
{0x349C+0x48*i} TX_RESPONSE_OK_CNT{i} (i=0..2) ro — Port {i} TX RESPONSE Frame Count Register
  [7:0] TX_RESPONSE_OK_CNT — Port n increments for every RESPONSE frame transmitted.
{0x34A0+0x48*i} RX_VERIFY_OK_CNT{i} (i=0..2) ro — Port {i} RX VERIFY Frame Count Register
  [7:0] RX_VERIFY_OK_CNT — Port n increments for every valid VERIFY frame received.
{0x34A4+0x48*i} RX_RESPONSE_OK_CNT{i} (i=0..2) ro — Port {i} RX RESPONSE Frame Count Register
  [7:0] RX_RESPONSE_OK_CNT — Port n increments for every valid RESPONSE frame received.
{0x34A8+0x48*i} RX_VERIFY_BAD_CNT{i} (i=0..2) ro — Port {i} RX Error VERIFY Frame Count Register
  [7:0] RX_VERIFY_BAD_CNT — Port n increments for every errored VERIFY frame received.
{0x34AC+0x48*i} RX_RESPONSE_BAD_CNT{i} (i=0..2) ro — Port {i} RX Error RESPONSE Frame Count Register
  [7:0] RX_RESPONSE_BAD_CNT — Port n increments for every errored RESPONSE frame received.
0x3B00 MMCTL_OUT_CT — Cut-Through Register
  [18:16] CT_OVR — 1 bit per-port value to set the Cut Through behavior of the output ports. When set to 0, all frames are sent as Store & Forward (SF) frames. When set to 1, frames with the CT flag set in the frame context are started as soon as the frame context information is available.
  [2:0] CT_OVR_ENA — Per-port bit mask to enable overriding the Cut-Through (CT) behavior of the output ports with CT_OVR. When set to 0, the frames are transmitted CT if the CT flag of the frame context is set.
0x3B04 MMCTL_CTFL_P0_3_ENA reset 0xFFFFFF — Cut-Through Frame Length Enable Register
  [23:16] CTFL_P2_ENA — Port 2 bit mask of n bits, where n is the number of queues per port indicating whether the CTFL is used for Cut-Through (CT) frames. When set to 1, a CT frame requires a CTFL entry to be written as a CT frame in the output memory.
  [15:8] CTFL_P1_ENA — Port 1 bit mask of n bits, where n is the number of queues per port indicating whether the CTFL is used for Cut-Through (CT) frames. When set to 1, a CT frame requires a CTFL entry to be written as a CT frame in the output memory.
  [7:0] CTFL_P0_ENA — Port 0 bit mask of n bits, where n is the number of queues per port indicating whether the CTFL is used for Cut-Through (CT) frames. When set to 1, a CT frame requires a CTFL entry to be written as a CT frame in the output memory.
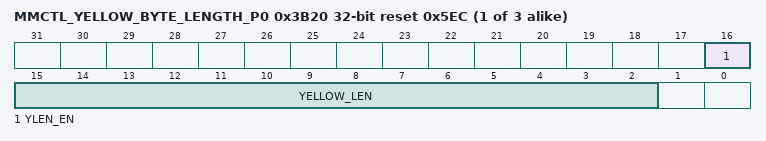
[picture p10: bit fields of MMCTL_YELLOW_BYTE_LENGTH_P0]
{0x3B20+4i} MMCTL_YELLOW_BYTE_LENGTH_P{i} (i=0..2) reset 0x5EC — Port {i} Yellow Period Byte Length Register
  [16] YLEN_EN — When set to 1, enables transmission when OUT_CT_ENA is low only if the frame length is less than YELLOW_LEN. If cleared, YELLOW_LEN is ignored and frames are always transmitted in SF mode when OUT_CT_ENA is 0.
  [15:2] YELLOW_LEN — Length in bytes of the YELLOW period for port n. Determines whether a frame can be transmitted before the YELLOW period expires. The value is programmed in increments of 4 bytes excluding the MAC overhead (IPG, Preamble and FCS if appended) of the frame.
